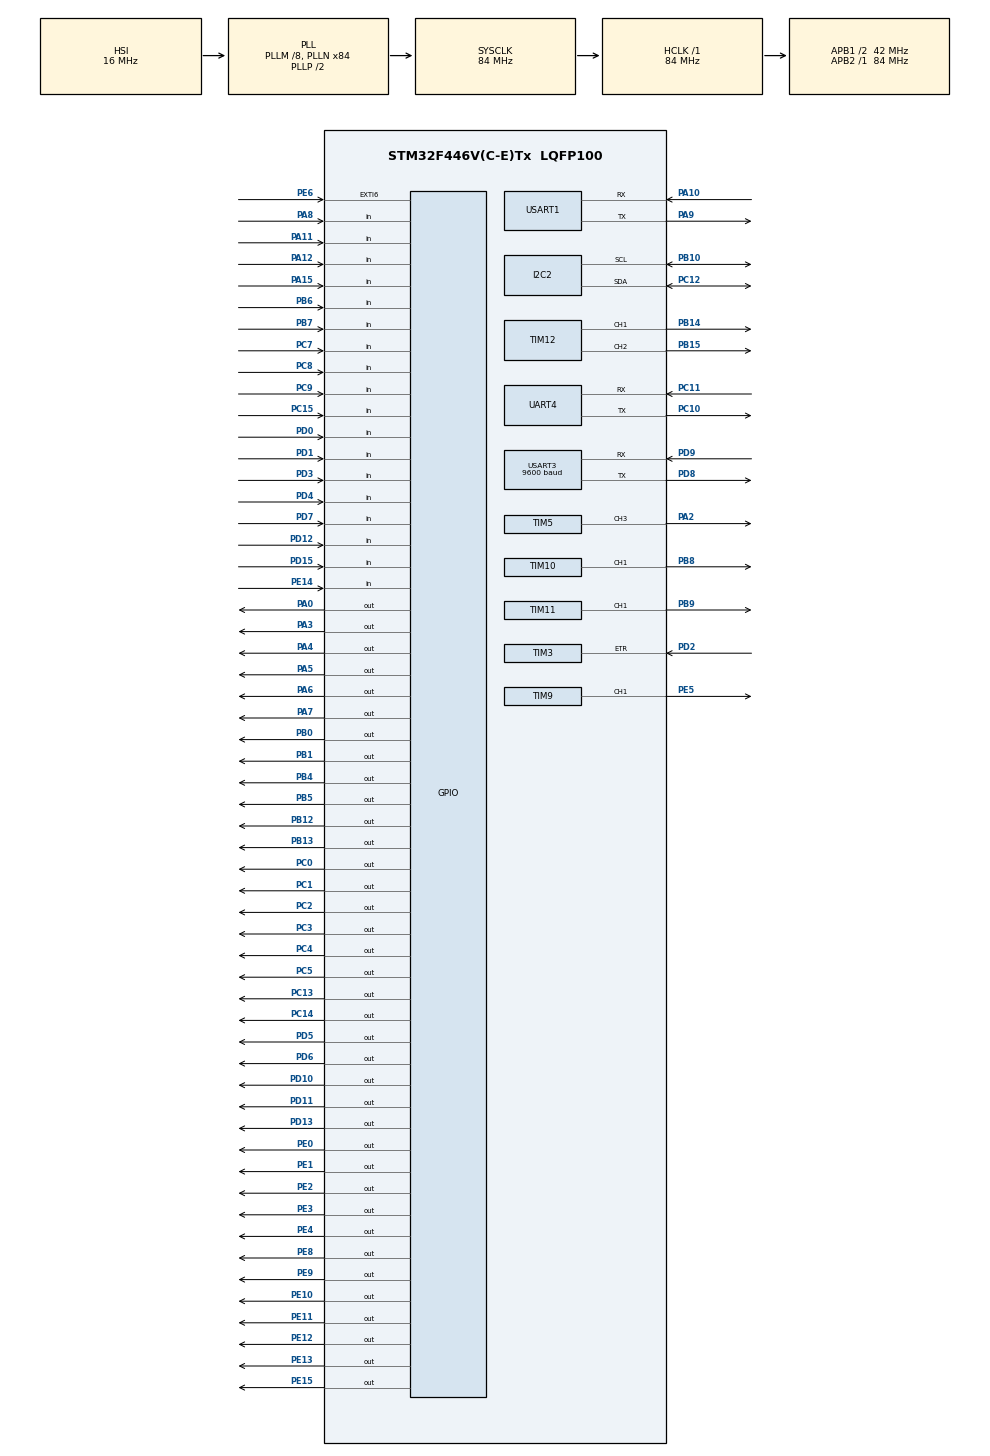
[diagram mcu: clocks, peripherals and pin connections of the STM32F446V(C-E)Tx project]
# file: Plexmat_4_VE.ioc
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I2C2.I2C_Mode=I2C_Fast
Mcu.Family=STM32F4
Mcu.Name=STM32F446V(C-E)Tx
Mcu.Package=LQFP100
NVIC.EXTI9_5_IRQn=true\:0\:0\:false\:false\:true\:true\:true\:true
NVIC.PriorityGroup=NVIC_PRIORITYGROUP_4
NVIC.TIM1_BRK_TIM9_IRQn=true\:0\:0\:false\:false\:true\:true\:true\:true
NVIC.TIM1_TRG_COM_TIM11_IRQn=true\:0\:0\:false\:false\:true\:true\:true\:true
NVIC.TIM1_UP_TIM10_IRQn=true\:0\:0\:false\:false\:true\:true\:true\:true
NVIC.TIM3_IRQn=true\:0\:0\:false\:false\:true\:true\:true\:true
NVIC.TIM5_IRQn=true\:0\:0\:false\:false\:true\:true\:true\:true
NVIC.TIM8_BRK_TIM12_IRQn=true\:0\:0\:false\:false\:true\:true\:true\:true
NVIC.USART1_IRQn=true\:0\:0\:false\:false\:true\:true\:true\:true
NVIC.USART3_IRQn=true\:0\:0\:false\:false\:true\:true\:true\:true
PA0-WKUP.Signal=GPIO_Output
PA10.Mode=Asynchronous
PA10.Signal=USART1_RX
PA11.Signal=GPIO_Input
PA12.Signal=GPIO_Input
PA15.Signal=GPIO_Input
PA2.Signal=S_TIM5_CH3
PA3.Signal=GPIO_Output
PA4.Signal=GPIO_Output
PA5.Signal=GPIO_Output
PA6.Signal=GPIO_Output
PA7.Signal=GPIO_Output
PA8.Signal=GPIO_Input
PA9.Mode=Asynchronous
PA9.Signal=USART1_TX
PB0.Signal=GPIO_Output
PB1.Signal=GPIO_Output
PB10.Mode=I2C
PB10.Signal=I2C2_SCL
PB12.Signal=GPIO_Output
PB13.Signal=GPIO_Output
PB14.Signal=S_TIM12_CH1
PB15.Signal=S_TIM12_CH2
PB4.Signal=GPIO_Output
PB5.Signal=GPIO_Output
PB6.Signal=GPIO_Input
PB7.Signal=GPIO_Input
PB8.Signal=S_TIM10_CH1
PB9.Signal=S_TIM11_CH1
PC0.Signal=GPIO_Output
PC1.Signal=GPIO_Output
PC10.Mode=Asynchronous
PC10.Signal=UART4_TX
PC11.Mode=Asynchronous
PC11.Signal=UART4_RX
PC12.Mode=I2C
PC12.Signal=I2C2_SDA
PC13.Signal=GPIO_Output
PC14-OSC32_IN.Signal=GPIO_Output
PC15-OSC32_OUT.Signal=GPIO_Input
PC2.Signal=GPIO_Output
PC3.Signal=GPIO_Output
PC4.Signal=GPIO_Output
PC5.Signal=GPIO_Output
PC6.Signal=S_TIM8_CH1
PC7.GPIO_PuPd=GPIO_PULLDOWN
PC7.Signal=GPIO_Input
PC8.GPIO_PuPd=GPIO_PULLDOWN
PC8.Signal=GPIO_Input
PC9.GPIO_PuPd=GPIO_PULLDOWN
PC9.Signal=GPIO_Input
PD0.GPIO_PuPd=GPIO_PULLDOWN
PD0.Signal=GPIO_Input
PD1.GPIO_PuPd=GPIO_PULLDOWN
PD1.Signal=GPIO_Input
PD10.Signal=GPIO_Output
PD11.Signal=GPIO_Output
PD12.GPIO_PuPd=GPIO_PULLDOWN
PD12.Signal=GPIO_Input
PD13.Signal=GPIO_Output
PD15.GPIO_PuPd=GPIO_PULLDOWN
PD15.Signal=GPIO_Input
PD2.Signal=S_TIM3_ETR
PD3.Signal=GPIO_Input
PD4.Signal=GPIO_Input
PD5.Signal=GPIO_Output
PD6.Signal=GPIO_Output
PD7.Signal=GPIO_Input
PD8.Mode=Asynchronous
PD8.Signal=USART3_TX
PD9.Mode=Asynchronous
PD9.Signal=USART3_RX
PE0.Signal=GPIO_Output
PE1.Signal=GPIO_Output
PE10.Signal=GPIO_Output
PE11.Signal=GPIO_Output
PE12.Signal=GPIO_Output
PE13.Signal=GPIO_Output
PE14.GPIO_PuPd=GPIO_PULLUP
PE14.Signal=GPIO_Input
PE15.Signal=GPIO_Output
PE2.Signal=GPIO_Output
PE3.Signal=GPIO_Output
PE4.Signal=GPIO_Output
PE5.Signal=S_TIM9_CH1
PE6.GPIO_PuPd=GPIO_PULLDOWN
PE6.Signal=GPXTI6
PE8.Signal=GPIO_Output
PE9.Signal=GPIO_Output
ProjectManager.HeapSize=0x200
ProjectManager.StackSize=0x400
ProjectManager.TargetToolchain=STM32CubeIDE
RCC.AHBFreq_Value=84000000
RCC.APB1CLKDivider=RCC_HCLK_DIV2
RCC.APB1Freq_Value=42000000
RCC.APB1TimFreq_Value=84000000
RCC.APB2Freq_Value=84000000
RCC.APB2TimFreq_Value=84000000
RCC.CortexFreq_Value=84000000
RCC.HCLKFreq_Value=84000000
RCC.PLLM=8
RCC.PLLN=84
RCC.SYSCLKFreq_VALUE=84000000
RCC.SYSCLKSource=RCC_SYSCLKSOURCE_PLLCLK
RCC.USBFreq_Value=84000000
RCC.VCOOutputFreq_Value=168000000
SH.S_TIM10_CH1.0=TIM10_CH1,PWM Generation1 CH1
SH.S_TIM11_CH1.0=TIM11_CH1,PWM Generation1 CH1
SH.S_TIM12_CH1.0=TIM12_CH1,PWM Generation1 CH1
SH.S_TIM12_CH2.0=TIM12_CH2,PWM Generation2 CH2
SH.S_TIM3_ETR.0=TIM3_ETR,TriggerSource_ETR
SH.S_TIM5_CH3.0=TIM5_CH3,PWM Generation3 CH3
SH.S_TIM8_CH1.0=TIM8_CH1
SH.S_TIM9_CH1.0=TIM9_CH1,PWM Generation1 CH1
TIM10.AutoReloadPreload=TIM_AUTORELOAD_PRELOAD_ENABLE
TIM10.Channel=TIM_CHANNEL_1
TIM10.Prescaler=84
TIM11.AutoReloadPreload=TIM_AUTORELOAD_PRELOAD_ENABLE
TIM11.Channel=TIM_CHANNEL_1
TIM11.Period=999
TIM11.Prescaler=84
TIM12.Channel-PWM\ Generation1\ CH1=TIM_CHANNEL_1
TIM12.Channel-PWM\ Generation2\ CH2=TIM_CHANNEL_2
TIM3.Slave_TriggerFilter=2
TIM5.Channel-PWM\ Generation3\ CH3=TIM_CHANNEL_3
TIM9.Channel-PWM\ Generation1\ CH1=TIM_CHANNEL_1
UART4.VirtualMode=Asynchronous
USART1.VirtualMode=VM_ASYNC
USART3.BaudRate=9600
USART3.VirtualMode=VM_ASYNC
VP_TIM10_VS_ClockSourceINT.Mode=Enable_Timer
VP_TIM11_VS_ClockSourceINT.Mode=Enable_Timer
VP_TIM12_VS_ClockSourceINT.Mode=Internal
VP_TIM13_VS_ClockSourceINT.Mode=Enable_Timer
VP_TIM3_VS_ControllerModeClock.Mode=Clock Mode
VP_TIM4_VS_ClockSourceINT.Mode=Internal
VP_TIM5_VS_ClockSourceINT.Mode=Internal
VP_TIM9_VS_ClockSourceINT.Mode=Internal
board=custom

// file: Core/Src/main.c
/* USER CODE BEGIN Header */
/**
  ******************************************************************************
  * @file           : main.c
  * @brief          : Main program body
  ******************************************************************************
  * @attention
  *
  * Copyright (c) 2025 STMicroelectronics.
  * All rights reserved.
  *
  * This software is licensed under terms that can be found in the LICENSE file
  * in the root directory of this software component.
  * If no LICENSE file comes with this software, it is provided AS-IS.
  *
  ******************************************************************************
  */
/* USER CODE END Header */
#include "main.h"
#include "i2c.h"
#include "tim.h"
#include "usart.h"
#include "gpio.h"

/* USER CODE BEGIN Includes */

#include "command_processor.h"

#include "commands.h"
#include "define.h"
/* USER CODE END Includes */

/* USER CODE BEGIN PV */
char* Error_Source = "None";
/* USER CODE END PV */

void SystemClock_Config(void);

int main(void)
{

  /* MCU Configuration--------------------------------------------------------*/

  /* Reset of all peripherals, Initializes the Flash interface and the Systick. */
  HAL_Init();

  /* Configure the system clock */
  SystemClock_Config();

  /* Initialize all configured peripherals */
  MX_GPIO_Init();
  MX_I2C2_Init();
  MX_TIM5_Init();
  MX_TIM9_Init();
  MX_TIM10_Init();
  MX_TIM11_Init();
  MX_TIM12_Init();
  MX_TIM13_Init();
  MX_UART4_Init();
  MX_USART1_UART_Init();
  MX_USART3_UART_Init();
  MX_TIM4_Init();
  MX_TIM3_Init();
  /* USER CODE BEGIN 2 */

	HAL_GPIO_WritePin(GPIOC, GPIO_PIN_4, GPIO_PIN_SET);
	Rising_Edge(VL_EXLED_GATE);
	HAL_GPIO_WritePin(GPIOC,GPIO_PIN_1,GPIO_PIN_RESET);
	HAL_GPIO_WritePin(GPIOC,GPIO_PIN_2,GPIO_PIN_RESET);
	HAL_GPIO_WritePin(GPIOC,GPIO_PIN_3,GPIO_PIN_RESET);
	HAL_GPIO_WritePin(GPIOE,GPIO_PIN_9,GPIO_PIN_RESET);
	HAL_GPIO_WritePin(GPIOE,GPIO_PIN_8,GPIO_PIN_RESET);
	HAL_GPIO_WritePin(GPIOE,GPIO_PIN_7,GPIO_PIN_RESET);
	HAL_GPIO_WritePin(GPIOB,GPIO_PIN_1,GPIO_PIN_RESET);
	HAL_GPIO_WritePin(GPIOB,GPIO_PIN_0,GPIO_PIN_RESET);

	HAL_GPIO_WritePin(GPIOE,GPIO_PIN_12,GPIO_PIN_RESET);
	HAL_GPIO_WritePin(GPIOE,GPIO_PIN_11,GPIO_PIN_RESET);
	HAL_GPIO_WritePin(GPIOE,GPIO_PIN_10,GPIO_PIN_RESET);
	HAL_GPIO_WritePin(GPIOE,GPIO_PIN_13,GPIO_PIN_RESET);
	HAL_GPIO_WritePin(GPIOE,GPIO_PIN_15,GPIO_PIN_RESET);

	HAL_GPIO_WritePin(GPIOC,GPIO_PIN_5,GPIO_PIN_RESET);

	HAL_GPIO_WritePin(GPIOA,GPIO_PIN_7,GPIO_PIN_RESET);
	HAL_GPIO_WritePin(GPIOA,GPIO_PIN_6,GPIO_PIN_RESET);
	HAL_GPIO_WritePin(GPIOA,GPIO_PIN_5,GPIO_PIN_RESET);
	HAL_GPIO_WritePin(GPIOA,GPIO_PIN_4,GPIO_PIN_RESET);
	HAL_GPIO_WritePin(GPIOA,GPIO_PIN_3,GPIO_PIN_RESET);
	HAL_GPIO_WritePin(GPIOA,GPIO_PIN_0,GPIO_PIN_RESET);
	HAL_GPIO_WritePin(GPIOB,GPIO_PIN_5,GPIO_PIN_RESET);// for epot 1 -write protect
	HAL_GPIO_WritePin(GPIOB,GPIO_PIN_4,GPIO_PIN_RESET);// for epot 2- write protect
	HAL_GPIO_WritePin(GPIOD,GPIO_PIN_6,GPIO_PIN_RESET);// for epot 3- write protect
	HAL_GPIO_WritePin(GPIOD,GPIO_PIN_5,GPIO_PIN_RESET);// for epot 4- write protect
	Rising_Edge(P1_P4_GATE);
	Rising_Edge(P5_P7_GATE);
	Rising_Edge(VL_EXLED_GATE);

	Syringe_Motor_Dis;   //if it is enabled, the 2.5 ml keyto syring will produce humming noise

	HAL_UART_Transmit(&huart3, (uint8_t *)"PLexMAT 4  V1.0\n",strlen("PLexMAT 4  V1.0\n"), 100);
	// Start UART reception (1 byte at a time)
	HAL_UART_Receive_IT(&huart3, &rxByte, 1);

	/* The below two lines are included becuse only the first command was not detected during the power cycle */
	//HAL_TIM_Base_Start_IT(&htim2); //  Start timeout timer
	//HAL_TIM_Base_Stop_IT(&htim2);  //  Stop timeout timer

//	  HAL_TIM_IC_Start_IT(&htim4, TIM_CHANNEL_1); // Start input capture with interrupt
	// Start TIM2 Input Capture with interrupt on channel 1
	//HAL_TIM_IC_Start_IT(&htim1, TIM_CHANNEL_4);

// Make Z Home -during power up

	 LED_Off(RedLED);
	 Rising_Edge(VL_EXLED_GATE);
	 LED_Off(YellowLED);
	 Rising_Edge(VL_EXLED_GATE);
	 LED_On(GreenLED);
	 Rising_Edge(VL_EXLED_GATE);
	 HAL_Delay(10);
	// Initialize last capture tick to current tick
//	last_capture_tick = HAL_GetTick();

		last_capture_tick = HAL_GetTick();

  /* USER CODE END 2 */

  /* Infinite loop */
  while (1)
  {

    /* USER CODE BEGIN 3 */
	  Start_Process();
  }
  /* USER CODE END 3 */
}

void SystemClock_Config(void)
{
  RCC_OscInitTypeDef RCC_OscInitStruct = {0};
  RCC_ClkInitTypeDef RCC_ClkInitStruct = {0};

  /** Configure the main internal regulator output voltage
  */
  __HAL_RCC_PWR_CLK_ENABLE();
  __HAL_PWR_VOLTAGESCALING_CONFIG(PWR_REGULATOR_VOLTAGE_SCALE3);

  /** Initializes the RCC Oscillators according to the specified parameters
  * in the RCC_OscInitTypeDef structure.
  */
  RCC_OscInitStruct.OscillatorType = RCC_OSCILLATORTYPE_HSI;
  RCC_OscInitStruct.HSIState = RCC_HSI_ON;
  RCC_OscInitStruct.HSICalibrationValue = RCC_HSICALIBRATION_DEFAULT;
  RCC_OscInitStruct.PLL.PLLState = RCC_PLL_ON;
  RCC_OscInitStruct.PLL.PLLSource = RCC_PLLSOURCE_HSI;
  RCC_OscInitStruct.PLL.PLLM = 8;
  RCC_OscInitStruct.PLL.PLLN = 84;
  RCC_OscInitStruct.PLL.PLLP = RCC_PLLP_DIV2;
  RCC_OscInitStruct.PLL.PLLQ = 2;
  RCC_OscInitStruct.PLL.PLLR = 2;
  if (HAL_RCC_OscConfig(&RCC_OscInitStruct) != HAL_OK)
  {
    Error_Handler();
  }

  /** Initializes the CPU, AHB and APB buses clocks
  */
  RCC_ClkInitStruct.ClockType = RCC_CLOCKTYPE_HCLK|RCC_CLOCKTYPE_SYSCLK
                              |RCC_CLOCKTYPE_PCLK1|RCC_CLOCKTYPE_PCLK2;
  RCC_ClkInitStruct.SYSCLKSource = RCC_SYSCLKSOURCE_PLLCLK;
  RCC_ClkInitStruct.AHBCLKDivider = RCC_SYSCLK_DIV1;
  RCC_ClkInitStruct.APB1CLKDivider = RCC_HCLK_DIV2;
  RCC_ClkInitStruct.APB2CLKDivider = RCC_HCLK_DIV1;

  if (HAL_RCC_ClockConfig(&RCC_ClkInitStruct, FLASH_LATENCY_2) != HAL_OK)
  {
    Error_Handler();
  }
}

void Error_Handler(void)
{
  __disable_irq();
  while (1)
  {
  }
}
